# MK80F25615 register map
Vendor: Freescale Semiconductor, Inc.; Series: Kinetis_K; File version: 1.6
CPU: CM4 r0p1, little endian, no MPU, FPU, VTOR, 4 interrupt priority bits
Registers are 32-bit, read-write, reset 0x0 unless marked. A register's access mark holds for its fields unless they carry their own. Offsets are from the block's base; [hi:lo] are bit positions; {n}, {i} and the like mark numbered series; 'fields as' and 'values as' point back to an identical list.

## PORTA — Pin Control and Interrupts
Base 0x40049000; register names take the prefix PORTA_
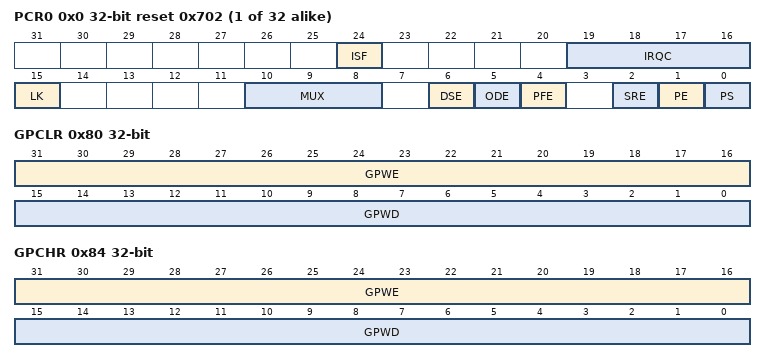
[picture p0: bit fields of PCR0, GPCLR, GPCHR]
{0x0+4i} PCR{i} (i=0..31) reset 0x702 — Pin Control Register n
  [24] ISF — Interrupt Status Flag
    0=Configured interrupt is not detected; 1=Configured interrupt is detected. If the pin is configured to generate a DMA request, then the corresponding flag will be cleared automatically at the completion of the requested DMA transfer. Otherwise, the flag remains set until a logic 1 is written to the flag. If the pin is configured for a level sensitive interrupt and the pin remains asserted, then the flag is set again immediately after it is cleared.
  [19:16] IRQC — Interrupt Configuration
    0=Interrupt Status Flag (ISF) is disabled; 1=ISF flag and DMA request on rising edge; 2=ISF flag and DMA request on falling edge; 3=ISF flag and DMA request on either edge; 8=ISF flag and Interrupt when logic 0; 9=ISF flag and Interrupt on rising-edge; 10=ISF flag and Interrupt on falling-edge; 11=ISF flag and Interrupt on either edge; 12=ISF flag and Interrupt when logic 1
  [15] LK — Lock Register
    0=Pin Control Register fields [15:0] are not locked; 1=Pin Control Register fields [15:0] are locked and cannot be updated until the next system reset
  [10:8] MUX — Pin Mux Control
    0=Pin disabled (Alternative 0) (analog); 1=Alternative 1 (GPIO); {v}=Alternative {v} (chip-specific) (v=2..7)
  [6] DSE — Drive Strength Enable
    0=Low drive strength is configured on the corresponding pin, if pin is configured as a digital output; 1=High drive strength is configured on the corresponding pin, if pin is configured as a digital output
  [5] ODE — Open Drain Enable
    0=Open drain output is disabled on the corresponding pin; 1=Open drain output is enabled on the corresponding pin, if the pin is configured as a digital output
  [4] PFE — Passive Filter Enable
    0=Passive input filter is disabled on the corresponding pin; 1=Passive input filter is enabled on the corresponding pin, if the pin is configured as a digital input. Refer to the device data sheet for filter characteristics.
  [2] SRE — Slew Rate Enable
    0=Fast slew rate is configured on the corresponding pin, if the pin is configured as a digital output; 1=Slow slew rate is configured on the corresponding pin, if the pin is configured as a digital output
  [1] PE — Pull Enable
    0=Internal pullup or pulldown resistor is not enabled on the corresponding pin; 1=Internal pullup or pulldown resistor is enabled on the corresponding pin, if the pin is configured as a digital input
  [0] PS — Pull Select
    0=Internal pulldown resistor is enabled on the corresponding pin, if the corresponding PE field is set; 1=Internal pullup resistor is enabled on the corresponding pin, if the corresponding PE field is set
0x80 GPCLR wo — Global Pin Control Low Register
  [31:16] GPWE — Global Pin Write Enable
    0=Corresponding Pin Control Register is not updated with the value in GPWD; 1=Corresponding Pin Control Register is updated with the value in GPWD
  [15:0] GPWD — Global Pin Write Data
0x84 GPCHR wo — Global Pin Control High Register
  fields as GPCLR
0xA0 ISFR — Interrupt Status Flag Register
  [31:0] ISF — Interrupt Status Flag
    values as PCR0.ISF

## EWM — External Watchdog Monitor
Base 0x40061000; register names take the prefix EWM_
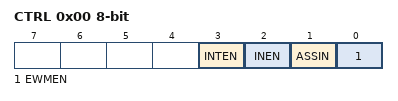
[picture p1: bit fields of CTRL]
0x00 CTRL 8-bit — Control Register
  [3] INTEN — Interrupt Enable.
  [2] INEN — Input Enable.
  [1] ASSIN — EWM_in's Assertion State Select.
  [0] EWMEN — EWM enable.
0x01 SERV 8-bit wo — Service Register
  [7:0] SERVICE — The EWM service mechanism requires the CPU to write two values to the SERV register: a first data byte of 0xB4, followed by a second data byte of 0x2C
0x02 CMPL 8-bit — Compare Low Register
  [7:0] COMPAREL — To prevent runaway code from changing this field, software should write to this field after a CPU reset even if the (default) minimum service time is required
0x03 CMPH 8-bit reset 0xFF — Compare High Register
  [7:0] COMPAREH — To prevent runaway code from changing this field, software should write to this field after a CPU reset even if the (default) maximum service time is required
0x04 CLKCTRL 8-bit — Clock Control Register
  [1:0] CLKSEL — EWM has 4 possible low power clock sources for running EWM counter
0x05 CLKPRESCALER 8-bit — Clock Prescaler Register
  [7:0] CLK_DIV — Selected low power clock source for running the EWM counter can be prescaled as below

## Notices in the file
Redistribution and use in source and binary forms, with or without modification,
are permitted provided that the following conditions are met:
o Redistributions of source code must retain the above copyright notice, this list
of conditions and the following disclaimer.
o Redistributions in binary form must reproduce the above copyright notice, this
list of conditions and the following disclaimer in the documentation and/or
other materials provided with the distribution.
o Neither the name of Freescale Semiconductor, Inc. nor the names of its
contributors may be used to endorse or promote products derived from this
software without specific prior written permission.
THIS SOFTWARE IS PROVIDED BY THE COPYRIGHT HOLDERS AND CONTRIBUTORS "AS IS" AND
ANY EXPRESS OR IMPLIED WARRANTIES, INCLUDING, BUT NOT LIMITED TO, THE IMPLIED
WARRANTIES OF MERCHANTABILITY AND FITNESS FOR A PARTICULAR PURPOSE ARE
DISCLAIMED. IN NO EVENT SHALL THE COPYRIGHT HOLDER OR CONTRIBUTORS BE LIABLE FOR
ANY DIRECT, INDIRECT, INCIDENTAL, SPECIAL, EXEMPLARY, OR CONSEQUENTIAL DAMAGES
(INCLUDING, BUT NOT LIMITED TO, PROCUREMENT OF SUBSTITUTE GOODS OR SERVICES;
LOSS OF USE, DATA, OR PROFITS; OR BUSINESS INTERRUPTION) HOWEVER CAUSED AND ON
ANY THEORY OF LIABILITY, WHETHER IN CONTRACT, STRICT LIABILITY, OR TORT
(INCLUDING NEGLIGENCE OR OTHERWISE) ARISING IN ANY WAY OUT OF THE USE OF THIS
SOFTWARE, EVEN IF ADVISED OF THE POSSIBILITY OF SUCH DAMAGE.
